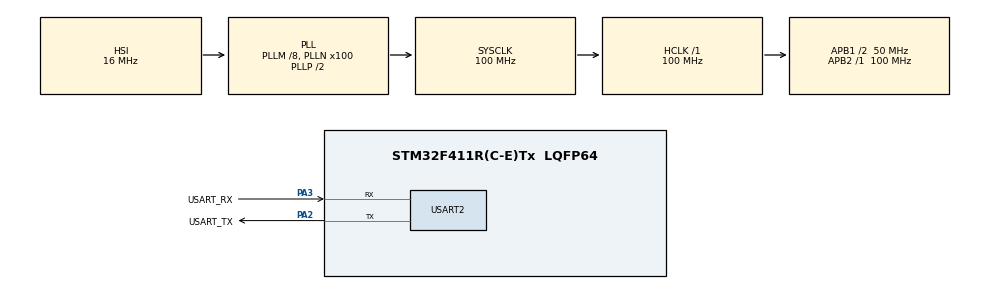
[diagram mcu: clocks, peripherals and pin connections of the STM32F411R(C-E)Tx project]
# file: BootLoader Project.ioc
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Mcu.Family=STM32F4
Mcu.Name=STM32F411R(C-E)Tx
Mcu.Package=LQFP64
NVIC.PriorityGroup=NVIC_PRIORITYGROUP_0
NVIC.TIM1_UP_TIM10_IRQn=true\:0\:0\:false\:false\:true\:true\:true\:true
PA13.Mode=Serial_Wire
PA13.Signal=SYS_JTMS-SWDIO
PA14.Mode=Serial_Wire
PA14.Signal=SYS_JTCK-SWCLK
PA2.GPIO_Label=USART_TX
PA2.Mode=Asynchronous
PA2.Signal=USART2_TX
PA3.GPIO_Label=USART_RX
PA3.Mode=Asynchronous
PA3.Signal=USART2_RX
ProjectManager.HeapSize=0x200
ProjectManager.StackSize=0x400
ProjectManager.TargetToolchain=MDK-ARM V5.32
RCC.48MHZClocksFreq_Value=50000000
RCC.AHBFreq_Value=100000000
RCC.APB1CLKDivider=RCC_HCLK_DIV2
RCC.APB1Freq_Value=50000000
RCC.APB1TimFreq_Value=100000000
RCC.APB2Freq_Value=100000000
RCC.APB2TimFreq_Value=100000000
RCC.CortexFreq_Value=100000000
RCC.FLatency-AdvancedSettings=FLASH_LATENCY_3
RCC.HCLKFreq_Value=100000000
RCC.HSE_VALUE=8000000
RCC.HSI_VALUE=16000000
RCC.LSE_VALUE=32768
RCC.PLLM=8
RCC.PLLN=100
RCC.SYSCLKFreq_VALUE=100000000
RCC.SYSCLKSource=RCC_SYSCLKSOURCE_PLLCLK
RCC.VCOOutputFreq_Value=200000000
TIM10.AutoReloadPreload=TIM_AUTORELOAD_PRELOAD_ENABLE
TIM10.Period=9999
TIM10.Prescaler=9999
USART2.VirtualMode=VM_ASYNC
VP_CRC_VS_CRC.Mode=CRC_Activate
VP_TIM10_VS_ClockSourceINT.Mode=Enable_Timer
board=NUCLEO-F411RE

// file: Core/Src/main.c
/* USER CODE BEGIN Header */
/**
  ******************************************************************************
  * @file           : main.c
  * @brief          : Main program body
  ******************************************************************************
  * @attention
  *
  * Copyright (c) 2026 STMicroelectronics.
  * All rights reserved.
  *
  * This software is licensed under terms that can be found in the LICENSE file
  * in the root directory of this software component.
  * If no LICENSE file comes with this software, it is provided AS-IS.
  *
  ******************************************************************************
  */
/* USER CODE END Header */
#include "main.h"
#include "crc.h"
#include "tim.h"
#include "usart.h"
#include "gpio.h"

/* USER CODE BEGIN Includes */

#include "bootloader.h"

/* USER CODE END Includes */

/* USER CODE BEGIN PV */
extern uint8_t go_to_user_app_flag;
extern uint8_t Host_Send_Data_Flag;
volatile uint8_t TIM10_1sec_counter = 0;
/* USER CODE END PV */

void SystemClock_Config(void);

int main(void)
{

  /* USER CODE BEGIN 1 */
	BL_Status status = BL_ACK;
  /* USER CODE END 1 */

  /* MCU Configuration--------------------------------------------------------*/

  /* Reset of all peripherals, Initializes the Flash interface and the Systick. */
  HAL_Init();

  /* Configure the system clock */
  SystemClock_Config();

  /* Initialize all configured peripherals */
  MX_GPIO_Init();
  MX_CRC_Init();
  MX_USART2_UART_Init();
  MX_TIM10_Init();
  /* USER CODE BEGIN 2 */
	HAL_TIM_Base_Start_IT(&htim10);
	status &= BL_Start_Message();
  /* USER CODE END 2 */

  /* Infinite loop */
  while (1)
  {

    /* USER CODE BEGIN 3 */
		if(TIM10_1sec_counter >= BOOTLOADER_TIMEOUT){
			Bootloader_Go_To_User_APP();
		}
		else{
			status &= BL_USART_Fetch_Host_Command();
			if(Host_Send_Data_Flag == BOOTLOADER_REC_DATA_FROM_HOST){
				TIM10_1sec_counter = 0;
				HAL_TIM_Base_Stop_IT(&htim10);
			}
			if(1 == go_to_user_app_flag){
				Bootloader_Go_To_User_APP();
			}
		}
  }
  /* USER CODE END 3 */
}

void SystemClock_Config(void)
{
  RCC_OscInitTypeDef RCC_OscInitStruct = {0};
  RCC_ClkInitTypeDef RCC_ClkInitStruct = {0};

  /** Configure the main internal regulator output voltage
  */
  __HAL_RCC_PWR_CLK_ENABLE();
  __HAL_PWR_VOLTAGESCALING_CONFIG(PWR_REGULATOR_VOLTAGE_SCALE1);

  /** Initializes the RCC Oscillators according to the specified parameters
  * in the RCC_OscInitTypeDef structure.
  */
  RCC_OscInitStruct.OscillatorType = RCC_OSCILLATORTYPE_HSI;
  RCC_OscInitStruct.HSIState = RCC_HSI_ON;
  RCC_OscInitStruct.HSICalibrationValue = RCC_HSICALIBRATION_DEFAULT;
  RCC_OscInitStruct.PLL.PLLState = RCC_PLL_ON;
  RCC_OscInitStruct.PLL.PLLSource = RCC_PLLSOURCE_HSI;
  RCC_OscInitStruct.PLL.PLLM = 8;
  RCC_OscInitStruct.PLL.PLLN = 100;
  RCC_OscInitStruct.PLL.PLLP = RCC_PLLP_DIV2;
  RCC_OscInitStruct.PLL.PLLQ = 4;
  if (HAL_RCC_OscConfig(&RCC_OscInitStruct) != HAL_OK)
  {
    Error_Handler();
  }

  /** Initializes the CPU, AHB and APB buses clocks
  */
  RCC_ClkInitStruct.ClockType = RCC_CLOCKTYPE_HCLK|RCC_CLOCKTYPE_SYSCLK
                              |RCC_CLOCKTYPE_PCLK1|RCC_CLOCKTYPE_PCLK2;
  RCC_ClkInitStruct.SYSCLKSource = RCC_SYSCLKSOURCE_PLLCLK;
  RCC_ClkInitStruct.AHBCLKDivider = RCC_SYSCLK_DIV1;
  RCC_ClkInitStruct.APB1CLKDivider = RCC_HCLK_DIV2;
  RCC_ClkInitStruct.APB2CLKDivider = RCC_HCLK_DIV1;

  if (HAL_RCC_ClockConfig(&RCC_ClkInitStruct, FLASH_LATENCY_3) != HAL_OK)
  {
    Error_Handler();
  }
}

/* USER CODE BEGIN 4 */
void HAL_TIM_PeriodElapsedCallback(TIM_HandleTypeDef *htim)

{
	if(htim->Instance == TIM10)
	{
		TIM10_1sec_counter++;
	}
}
/* USER CODE END 4 */

void Error_Handler(void)
{
  __disable_irq();
  while (1)
  {
  }
}
